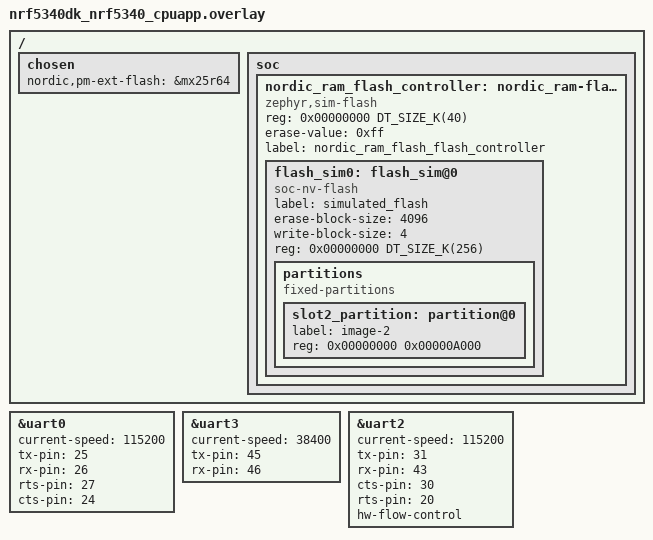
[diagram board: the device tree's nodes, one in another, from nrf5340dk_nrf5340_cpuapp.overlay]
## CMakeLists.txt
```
# SPDX-License-Identifier: Apache-2.0

cmake_minimum_required(VERSION 3.20.0)

list(APPEND ZEPHYR_EXTRA_MODULES ${CMAKE_CURRENT_SOURCE_DIR}/../ubxlib)
find_package(Zephyr REQUIRED HINTS $ENV{ZEPHYR_BASE})
project(celllocate_wifi_example)

FILE(GLOB app_sources src/*.c)
FILE(GLOB head_sources src/*.h)

target_include_directories(app PRIVATE ${CMAKE_CURRENT_SOURCE_DIR}/src)
target_sources(app PRIVATE ${app_sources})
target_sources(app PRIVATE ${head_sources})
```

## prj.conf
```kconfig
CONFIG_SOC_SERIES_NRF53X=y
CONFIG_SERIAL=y
CONFIG_UART_NRFX=y

CONFIG_CONSOLE_SUBSYS=y
CONFIG_CONSOLE_GETCHAR=y


# docs at https://docs.zephyrproject.org/latest/reference/kconfig/index.html
CONFIG_DEBUG=y
CONFIG_MINIMAL_LIBC=n
# This is the memory used by the porting layer
CONFIG_HEAP_MEM_POOL_SIZE=131072
CONFIG_USERSPACE=y
CONFIG_NET_BUF_USER_DATA_SIZE=4

CONFIG_MINIMAL_LIBC_MALLOC=n

# Enable ubxlib
CONFIG_UBXLIB=y

#CONFIG_UBXLIB_GNSS=y

CONFIG_UART_INTERRUPT_DRIVEN=y

#To get uPortTaskStackMinFree() working
CONFIG_INIT_STACKS=y
CONFIG_THREAD_STACK_INFO=y
CONFIG_THREAD_NAME=y

# To be able to use semaphore from ISR
CONFIG_IRQ_OFFLOAD=y

#Sufficient main stack to pass all tests and leave
#5 kbytes slack for user code
CONFIG_MAIN_STACK_SIZE=7048

# Add the basic Zephyr random number generator.
# IMPORTANT: this is only psuedo-random and is unlikely
# to be  sufficient for your needs, please check/test
# if you are intending to build production code.
CONFIG_TEST_RANDOM_GENERATOR=n
CONFIG_ENTROPY_DEVICE_RANDOM_GENERATOR=n

# Don't hide any potential errors
CONFIG_ASSERT=y

# SEGGER RTT logging instead of UART
CONFIG_LOG=y
CONFIG_LOG_DEFAULT_LEVEL=3
#If Log level 4 is set the log stack size needs to be increased
#CONFIG_LOG_PROCESS_THREAD_STACK_SIZE=8096
CONFIG_USE_SEGGER_RTT=n
CONFIG_RTT_CONSOLE=n
CONFIG_UART_CONSOLE=y
CONFIG_LOG_BACKEND_UART=y
CONFIG_LOG_BACKEND_SHOW_COLOR=y
# End of SEGGER RTT

# Enable debug thread info
CONFIG_OPENOCD_SUPPORT=y
CONFIG_DEBUG_OPTIMIZATIONS=y 
CONFIG_DEBUG_THREAD_INFO=y

# Enable bootloader application
CONFIG_BOOTLOADER_MCUBOOT=y

#Enable shell
CONFIG_SHELL=y
CONFIG_SHELL_STACK_SIZE=4096
CONFIG_SHELL_CMDS=n
CONFIG_KERNEL_SHELL=n
CONFIG_DEVICE_SHELL=n
CONFIG_DEVMEM_SHELL=n
CONFIG_FLASH_SHELL=n
CONFIG_PWM_SHELL=n
CONFIG_CLOCK_CONTROL_NRF_SHELL=n
CONFIG_I2C_SHELL=n
```

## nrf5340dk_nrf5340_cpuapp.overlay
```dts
/*
 * Copyright (c) 2021 Nordic Semiconductor ASA
 *
 * SPDX-License-Identifier: LicenseRef-Nordic-5-Clause
 */

/ {
	chosen {
		nordic,pm-ext-flash = &mx25r64;
	};

	soc {
		/* Add a flash controller which has the compatible
		 * 'zephyr,sim-flash'. This will ensure that the flash
		 * simulator can use it. None of the other properties in this
		 * node is used for anything.
		 */
		nordic_ram_flash_controller: nordic_ram-flash-controller@0 {
			compatible = "zephyr,sim-flash";
			reg = <0x00000000 DT_SIZE_K(40)>;
			#address-cells = <1>;
			#size-cells = <1>;
			erase-value = <0xff>;
			label = "nordic_ram_flash_flash_controller";

			/* This node label must match that used in the flash
			 * simulator.
			 */
			flash_sim0: flash_sim@0 {
				status = "okay";
				compatible = "soc-nv-flash";
				label = "simulated_flash";
				erase-block-size = <4096>;
				write-block-size = <4>;
				reg = <0x00000000 DT_SIZE_K(256)>;

				partitions {
					compatible = "fixed-partitions";
					#address-cells = <1>;
					#size-cells = <1>;

					/* This partition must be defined for
					 * MCUboot to find the partition ID
					 * of the primary slot for image 1,
					 * which is stored in this partition.
					 */
					slot2_partition: partition@0 {
						label = "image-2";
						reg = <0x00000000 0x00000A000>;
					};
				};
			};
		};
	};
};


// console uart
&uart0 {
	status = "okay";
	current-speed = <115200>;
	tx-pin = <25>;
	rx-pin = <26>;
	rts-pin = <27>;
	cts-pin = <24>;
};


// MaxM10S uart
&uart3 {
	status = "okay";
	current-speed = <38400>;
	tx-pin = <45>;
	rx-pin = <46>;
};

// Default configuration is set on the NINA-W156 pins, the same UART is also used by SARA-R5
&uart2 {
	status = "okay";
	current-speed = <115200>;
	tx-pin = <31>;  
	rx-pin = <43>;
	cts-pin = <30>;  
	rts-pin = <20>;  
	hw-flow-control;
};
```

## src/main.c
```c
/*
 * Copyright 2020 u-blox
 *
 * Licensed under the Apache License, Version 2.0 (the "License");
 * you may not use this file except in compliance with the License.
 * You may obtain a copy of the License at
 *
 *  http://www.apache.org/licenses/LICENSE-2.0
 *
 * 
 * Unless required by applicable law or agreed to in writing, software
 * distributed under the License is distributed on an "AS IS" BASIS,
 * WITHOUT WARRANTIES OR CONDITIONS OF ANY KIND, either express or implied.
 * See the License for the specific language governing permissions and
 * limitations under the License.
 */


/** 
 * @file main.c
 * @brief Example code for XPLR-IoT-1 Kit to demonstrate CellLocate usage with Sara R5 and Nina-W15 modules.
 */

#include <stddef.h>
#include <stdint.h>
#include <stdbool.h>
#include <stdlib.h>

#include "ubxlib.h"
#include "u_cfg_os_platform_specific.h"

#include <zephyr.h>
#include <console/console.h>
#include <shell/shell.h>
#include <device.h>
#include <devicetree.h>
#include <shell/shell_uart.h> 

#include "module_config.h"


/* ----------------------------------------------------------------
 * COMPILE-TIME MACROS
 * -------------------------------------------------------------- */

#define CELL_LOCATE_TOKEN_MAXLEN   25
#define CELL_LOCATE_SERVER_URL_MAXLEN  100
#define APN_MAXLEN 50
#define U_WIFI_UART_BUFFER_LENGTH_BYTES 600
#define VERIFY(cond, fail_msg) \
    if (!(cond)) {\
        failed(fail_msg); \
    }

/* ------------------------------------------------------------------------------
 * CALLBACK DECLERATIONS
 * -----------------------------------------------------------------------------*/

/** \fn static bool continueCellSearchCallback(uDeviceHandle_t deviceHandle)
 * @brief Indication to stop or continue CellConnect.
 * @param[in] deviceHandle device handle
*/
static bool continueCellSearchCallback(uDeviceHandle_t deviceHandle);


/* ------------------------------------------------------------------------------
 * HELPER FUNCTION DECLERATIONS
 * -----------------------------------------------------------------------------*/

/** \fn void failed(const char *msg)
 * @brief Function to log failed messages.
 * @param[in] msg incoming string - const char array
*/
void failed(const char *msg);

/** \fn char latLongToBits(int32_t thingX1e7, int32_t *pWhole, int32_t *pFraction)
 * @brief Convert a lat/long into a whole number and a bit-after-the-decimal-point that can be printed by a version of printf() 
 * that does not support floating point operations, returning the prefix (either "+" or "-").
 * The result should be printed with printf() format specifiers %c%d.%07d, e.g. something like:
 * int32_t whole;
 * int32_t fraction;
 * printf("%c%d.%07d/%c%d.%07d", latLongToBits(latitudeX1e7, &whole, &fraction),
 *                               whole, fraction,
 *                               latLongToBits(longitudeX1e7, &whole, &fraction),
 *                               whole, fraction);
 */
char latLongToBits(int32_t thingX1e7, int32_t *pWhole, int32_t *pFraction);

/** \fn void printLocation(int32_t latitudeX1e7, int32_t longitudeX1e7)
 * @brief Print lat/long location as a clickable link.
 * @param[in] latitudeX1e7 Latitude upto 7 decimal points
 * @param[in] longitudeX1e7 Longitude upto 7 decimal points
*/
void printLocation(int32_t latitudeX1e7, int32_t longitudeX1e7);

/** \fn int32_t getWifiScanPayload(char *pBuffer, int32_t bufferLength)
 * @brief Get Wi-Fi Access Points 
 * @param[in] pBuffer char array to be filled with APs information
 * @param[in] bufferLength maximum length of the buffer
 * @param[out] count length of the string received after Wi-Fi scan 
*/
int32_t getWifiScanPayload(char *pBuffer, int32_t bufferLength);


/** \fn uint8_t getPosition(char *pBuffer, uLocation_t *location, bool useWifiPayload)
 * @brief Function to get location using CellLocate service
 * @param[in] pBuffer input buffer containing wifi payload if set to USE_WIFI
 * @param[out] location To be filled when location is calculated
 * @param[in] useWifiPayload A flag that indicates to use WIFI location if set to 1. 
*/
uint8_t getPosition(char *pBuffer, uLocation_t *location);

/** \fn static int locationWifiHandler(const struct shell *shell, size_t argc, char **argv)
 * @brief WiFi command handler function to get location using CellLocate service with WiFi
 * @param[in] shell pointer to shell instance
 * @param[in] argc count of arugments
 * @param[in] argv pointer to array of arguments passed. 
*/
static int locationWifiHandler(const struct shell *shell, size_t argc, char **argv);

/** \fn static int locationCellHandler(const struct shell *shell, size_t argc, char **argv)
 * @brief Cell command handler function to get location using CellLocate service
 * @param[in] shell pointer to shell instance
 * @param[in] argc count of arugments
 * @param[in] argv pointer to array of arguments passed. 
*/
static int locationCellHandler(const struct shell *shell, size_t argc, char **argv);

/** \fn static int getConfigParameters(const struct shell *shell, size_t argc, char **argv)
 * @brief Function to read configuration parameters
 * @param[in] shell pointer to shell instance
 * @param[in] argc count of arugments
 * @param[in] argv pointer to array of arguments passed. 
*/
static int getConfigParameters(const struct shell *shell, size_t argc, char **argv);

/** \fn static int setConfigParameters(const struct shell *shell, size_t argc, char **argv)
 * @brief Function to set configuration parameters
 * @param[in] shell pointer to shell instance
 * @param[in] argc count of arugments
 * @param[in] argv pointer to array of arguments passed. 
*/
static int setConfigParameters(const struct shell *shell, size_t argc, char **argv);

/* ------------------------------------------------------------------------------
 * GLOBALS
 * -----------------------------------------------------------------------------*/

int wifiApSignalStrength = -90;
int numWifiAP = 15;
// CELL LOCATE Service Token 
char cellLocateToken[CELL_LOCATE_TOKEN_MAXLEN+1];
// CELL LOCATE Server address
char cellLocateServerUrl[CELL_LOCATE_SERVER_URL_MAXLEN+1]="cell-live1.services.u-blox.com";
// APN name to set for the network
char aPN[APN_MAXLEN+1]="tsiot";
// Timeout for Cell Registration in seconds
int32_t cellRegistrationTimeout = 40; 
// variable to keep connection attempt time
uint32_t cellNetConnectStartTime;
// flag to indicate whether the configuration is done or not 
bool configurationDone = false;

/* ------------------------------------------------------------------------------
 * CALLBACK IMPLEMENTATION
 * -----------------------------------------------------------------------------*/

static bool continueCellSearchCallback(uDeviceHandle_t deviceHandle)
{
    return (k_uptime_get() - cellNetConnectStartTime < (cellRegistrationTimeout*1000));
}

/* ------------------------------------------------------------------------------
 * HELPER FUNCTION IMPLEMENTATION
 * -----------------------------------------------------------------------------*/

void failed(const char *msg)
{
    uPortLog(msg);
    while(1);
}

char latLongToBits(int32_t thingX1e7, int32_t *pWhole, int32_t *pFraction)
{
    char prefix = '+';

    // Deal with the sign
    if (thingX1e7 < 0) {
        thingX1e7 = -thingX1e7;
        prefix = '-';
    }
    *pWhole = thingX1e7 / 10000000;
    *pFraction = thingX1e7 % 10000000;

    return prefix;
}

void printLocation(int32_t latitudeX1e7, int32_t longitudeX1e7)
{
    char prefixLat ;
    char prefixLong;
    int32_t wholeLat = 0;
    int32_t wholeLong = 0;
    int32_t fractionLat = 0;
    int32_t fractionLong = 0;
    prefixLat = latLongToBits(latitudeX1e7, &wholeLat, &fractionLat);
    prefixLong = latLongToBits(longitudeX1e7, &wholeLong, &fractionLong);
    printk("Position Lat: %c%d.%07d, Lon: %c%d.%07d\n",
             prefixLat, wholeLat, fractionLat, prefixLong, wholeLong,
             fractionLong);
    printk("Map URL: https://maps.google.com/?q=%c%d.%07d,%c%d.%07d\n",
             prefixLat, wholeLat, fractionLat, prefixLong, wholeLong,
             fractionLong);
}

int32_t getWifiScanPayload(char *pBuffer, int32_t bufferLength)
{
    printk("Preparing to get WiFi Scan Payload..\r\n");
    int32_t uartHandle;
    uAtClientHandle_t atClientHandle;
    int count = 0;

    memset(pBuffer,0,bufferLength);
    ninaNoraCommEnable();
    setUartConfig(NORAuart);
    printk("Nora UART configured \r\n");
    
    // Open a UART with the recommended buffer length
    // on your chosen UART HW block
    uartHandle = uPortUartOpen(2,
                               115200, NULL,
                               U_WIFI_UART_BUFFER_LENGTH_BYTES,
                               -1,
                               -1,
                               -1,
                               -1);

    // Add an AT client on the UART with the recommended
    // default buffer size.
    atClientHandle = uAtClientAdd(uartHandle,
                                  U_AT_CLIENT_STREAM_TYPE_UART,
                                  NULL,
                                  U_WIFI_UART_BUFFER_LENGTH_BYTES);

    
    // Set printing of AT commands by the cellular driver,
    // which can be useful while debugging.
    uAtClientPrintAtSet(atClientHandle, true);
    uAtClientLock(atClientHandle);
    printk("Setting AT client timeout \r\n");
    uAtClientTimeoutSet(atClientHandle, 5000);
	uAtClientFlush(atClientHandle);
    // Command to perform a Wi-Fi scan operation and outputs Wi-Fi Location fingerprint
    // AT+ULOCWIFIFMT=<numAPs>,<rssiFilter>,<format>
    printk("Requesting Wi-Fi location fingerprint \r\n");
    uAtClientCommandStart(atClientHandle, "AT+ULOCWIFIFMT=");
    uAtClientWriteInt(atClientHandle, numWifiAP);
    uAtClientWriteInt(atClientHandle, wifiApSignalStrength);
    uAtClientWriteInt(atClientHandle, 0);
    uAtClientCommandStop(atClientHandle);

    //Waiting for the response
    if (uAtClientResponseStart(atClientHandle, "+ULOCWIFIFMT:") == 0)
    {
        count = uAtClientReadString(atClientHandle, pBuffer, bufferLength, false);
    }
    uAtClientResponseStop(atClientHandle);
    uAtClientFlush(atClientHandle);
    uAtClientUnlock(atClientHandle);

    uAtClientRemove(atClientHandle);
    uPortUartClose(uartHandle);
    ninaNoraCommDisable();
    printk("NINA Payload(%d) : %s\r\n",count, pBuffer);
    return count;

}

uint8_t getPosition(char *pBuffer, uLocation_t *location)
{
    int32_t uartHandle;
    uAtClientHandle_t atClientHandle;
    uDeviceHandle_t cellHandle;
    
    int32_t numofRetries = 2;
    int32_t errorCode = -1;
    uint8_t locationReceived = U_ERROR_COMMON_UNKNOWN;
    printk("Turning on SARA-R5..\r\n");
    saraR5InitPower();
    setUartConfig(SARAuart);
    
    
    // Open a UART with the recommended buffer length
    // on your chosen UART HW block
    uartHandle = uPortUartOpen(2,
                               115200, NULL,
                               U_CELL_UART_BUFFER_LENGTH_BYTES,
                               -1,
                               -1,
                               -1,
                               -1);

    // Add an AT client on the UART with the recommended
    // default buffer size.
    atClientHandle = uAtClientAdd(uartHandle,
                                  U_AT_CLIENT_STREAM_TYPE_UART,
                                  NULL,
                                  U_CELL_AT_BUFFER_LENGTH_BYTES);

    uCellAdd(U_CELL_MODULE_TYPE_SARA_R5,
                          atClientHandle,
                          -1,
                          -1,
                          -1, false, &cellHandle);

    // Set printing of AT commands by the cellular driver,
    // which can be useful while debugging.                      
    uAtClientPrintAtSet(atClientHandle, true);
    uAtClientLock(atClientHandle);
    
    // AT command To disable echo
    uAtClientCommandStart(atClientHandle, "ATE0");
    uAtClientCommandStopReadResponse(atClientHandle);
    
    // AT+CMEE AT command enable or disable the use of result code
    // Enable +CME ERROR: result code and use verbose values
    uAtClientCommandStart(atClientHandle, "AT+CMEE=2");
    uAtClientCommandStopReadResponse(atClientHandle);
    uAtClientUnlock(atClientHandle);
    cellNetConnectStartTime = k_uptime_get();
    for (int i= 0; i< numofRetries &&  errorCode!= 0; i++){
        errorCode = uCellNetConnect(cellHandle, NULL, aPN, NULL, NULL, continueCellSearchCallback);
        uPortTaskBlock (500);
    }
    if (errorCode == 0) {
        // Configure Cell Locate service
        if (uCellLocSetServer(cellHandle, cellLocateToken, cellLocateServerUrl, NULL)==0){ 
            
            if (pBuffer != NULL){
                // feed wifi scan info to cellular module
                uAtClientLock(atClientHandle);

                // Configures the external location sensor used with the +ULOC command
                // Observation tags message in hexadecimal format
                // Set AT+ULOCEXT=<ULOCEXT_string>
                uAtClientCommandStart(atClientHandle, "AT+ULOCEXT=");
                uAtClientWriteString(atClientHandle, pBuffer, true);
                uAtClientCommandStopReadResponse(atClientHandle);
                uAtClientUnlock(atClientHandle);
            }
            
            // Now get location using Cell Locate
            if (uLocationGet(cellHandle, U_LOCATION_TYPE_CLOUD_CELL_LOCATE,
                            NULL, NULL,
                            location, NULL) == 0) {
                locationReceived = U_ERROR_COMMON_SUCCESS;

            } 
            
        }
    }
    else {
        printk("Cellular module not able to connect to network.\r\n");
    }
    
    uCellRemove(cellHandle);
    uAtClientRemove(atClientHandle);
    uPortUartClose(uartHandle);
    saraR5Disable();
    printk("SARA-R5 powered off \r\n");
    return locationReceived;
}

static int locationWifiHandler(const struct shell *shell, size_t argc, char **argv)
{
    if (configurationDone == false){
        shell_print(shell, "Before requesting location please complete the parameter configuration using config command\r\n");
        return 1;
    }
    unsigned char buffer[1023];
    uLocation_t location;
    int32_t rc = U_ERROR_COMMON_NOT_INITIALISED;
    if (getWifiScanPayload(buffer, sizeof(buffer)) > 0 )
    {
        if (getPosition(buffer, &location) == U_ERROR_COMMON_SUCCESS) {
            printLocation((int32_t)location.latitudeX1e7, (int32_t)location.longitudeX1e7);
            rc = U_ERROR_COMMON_SUCCESS;
        }
        else {
            shell_print(shell, "Could not get location.\r\n");
        }
    }
    else {
        shell_print(shell, "No WiFi AP information available. Please adjust filter conditions according to the environment\r\n");
    }
    
    return 0;
    
}

static int locationCellHandler(const struct shell *shell, size_t argc, char **argv)
{
    if (configurationDone == false){
        shell_print(shell, "Before requesting location please complete the parameter configurtion using config command\r\n");
        return 1;
    }
    int32_t rc = U_ERROR_COMMON_UNKNOWN;
    uLocation_t location;
    if (getPosition(NULL, &location) == U_ERROR_COMMON_SUCCESS) {
        printLocation((int32_t)location.latitudeX1e7, (int32_t)location.longitudeX1e7);
        rc = U_ERROR_COMMON_SUCCESS;
    }
    else {
        printk("Could not get location.\r\n");
    }
    return 0;
}

static int getConfigParameters(const struct shell *shell, size_t argc, char **argv)
{
    shell_print(shell, "CellLocateServerURL: %s, Token: %s, APN: %s, CellRegistrationTimeout: %d, NumWifiAp: %d, WifiApSignalStrength: %d\r\n",\
    cellLocateServerUrl, \
    cellLocateToken,\
    aPN,\
    cellRegistrationTimeout, \
    numWifiAP,\
    wifiApSignalStrength);
    
    return 0;

}

static int setConfigParameters(const struct shell *shell, size_t argc, char **argv)
{
    if (argc == 7){
        bool invalid = false;
        uint32_t integerParameter;
        // checks parameters validity
        if( strlen( argv[1] ) >= CELL_LOCATE_SERVER_URL_MAXLEN ){
            shell_error( shell," CellLocateServerURL length cannot be greater than %d\r\n", CELL_LOCATE_SERVER_URL_MAXLEN );    
            invalid = true;
        }
        if( strlen( argv[2] )  >= CELL_LOCATE_TOKEN_MAXLEN ){
            shell_error( shell,"Token length cannot be greater than %d\r\n", CELL_LOCATE_TOKEN_MAXLEN );    
            invalid = true;
        }
        if( strlen( argv[3] ) >= APN_MAXLEN ){
            shell_error( shell,"APN length cannot be greater than %d\r\n", APN_MAXLEN );    
            invalid = true;
        }
        integerParameter = atoi(argv[4]);
        if(integerParameter < 0 && integerParameter >= 300 ){
            shell_error( shell,"CellRegistrationTimeout should be in between 1-300 seconds\r\n");    
            invalid = true;
        }
        integerParameter = atoi(argv[5]);
        if(integerParameter < 5 && integerParameter > 15 ){
            shell_error( shell,"NumWifiAP should be in between 5-15\r\n");    
            invalid = true;
        }
        integerParameter = atoi(argv[6]);
        if(integerParameter < -100 && integerParameter > 0 ){
            shell_error( shell,"WifiApSignalStrength should be in between -100-0\r\n");    
            invalid = true;
        }
        if( invalid ){
            return 1;
        }

        strcpy(cellLocateServerUrl, argv[1]);
        strcpy(cellLocateToken, argv[2]);
        strcpy(aPN, argv[3]);
        cellRegistrationTimeout = atoi(argv[4]);
        numWifiAP = atoi(argv[5]);
        wifiApSignalStrength = atoi(argv[6]);
        configurationDone = true;
        getConfigParameters(shell, argc, argv);

    }
    else {
        shell_print(shell, "Missing params. Please enter all parameters: <CellLocateServerURL> <Token> <APN> <CellRegistrationTimeout(s)> <NumWifiAp> <WifiApSignalStrength(dbm)>\r\n");
    }
    return 0;
}

/* ------------------------------------------------------------------------------
 * SHELL COMMANDS
 * 1- config
 * 	1a- config set <CellLocateServerURL> <Token> <APN> <CellRegistrationTimeout(s)> <NumWifiAp> <WifiApSignalStrength(dbm)
 * 	1b- config get
 * 2- location LocationType 
 * LocationType refers to cell or wifi 
 * -----------------------------------------------------------------------------*/

//2nd level of options 
SHELL_STATIC_SUBCMD_SET_CREATE(location_type,
        SHELL_CMD(wifi, NULL, "Use wifi access points information to get location",
                                               locationWifiHandler),
        SHELL_CMD(cell,   NULL, "Use cellular scan information to get location", locationCellHandler),
        SHELL_SUBCMD_SET_END
);
SHELL_STATIC_SUBCMD_SET_CREATE(config_sub_cmd,
        SHELL_CMD(get, NULL, "read configuration parameters",
                                               getConfigParameters),
        SHELL_CMD(set,   NULL, "set configuration parameters: <CellLocateServerURL> <Token> <APN> <CellRegistrationTimeout(s)> <NumWifiAp> <WifiApSignalStrength(dbm)>", setConfigParameters),
        SHELL_SUBCMD_SET_END
);

//1st level of options
SHELL_CMD_REGISTER(location, &location_type, "location command", NULL);
SHELL_CMD_REGISTER(config, &config_sub_cmd, "Configuration of parameters", NULL);
/* ----------------------------------------------------------------
 * MAIN FUNCTION
 * -------------------------------------------------------------- */

void main(void)
{   
    nina15InitPower();
    printk("NINA-W15 powered on \r\n");
    VERIFY(uPortInit() == 0, "uPortInit failed\r\n");
    uAtClientInit();
    uDeviceInit(); 
    uCellInit();
    printk("Enter your required shell commands. Type help for further details");
	
}
```

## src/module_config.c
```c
/*
 * Copyright 2020 u-blox
 *
 * Licensed under the Apache License, Version 2.0 (the "License");
 * you may not use this file except in compliance with the License.
 * You may obtain a copy of the License at
 *
 *  http://www.apache.org/licenses/LICENSE-2.0
 *
 * Unless required by applicable law or agreed to in writing, software
 * distributed under the License is distributed on an "AS IS" BASIS,
 * WITHOUT WARRANTIES OR CONDITIONS OF ANY KIND, either express or implied.
 * See the License for the specific language governing permissions and
 * limitations under the License.
 */


/** 
 * @file module_config.c
 * @brief Functions for different configurations of all the modules on XPLR-IOT-1 Kit
 */

#include "module_config.h"
#include <zephyr.h>
#include <hal/nrf_gpio.h>
#include <hal/nrf_uarte.h>
#include <drivers/uart.h>


/*!
 * @brief Sara uart configuration 
 */
UARTE_PSEL_Type SARA ={
    SARA_UART_RTS,
    SARA_UART_TX,
    SARA_UART_CTS,
    SARA_UART_RX
};

/*!
 * @brief Nora uart configuration 
 */
UARTE_PSEL_Type NORA ={
    NORA_UART_RTS,
    NORA_UART_TX,
    NORA_UART_CTS,
    NORA_UART_RX
};


/** \fn nina15ResetEnable(void)
 * @brief Enabling reset on Nina-W15
*/
void nina15ResetEnable(void)
{
    // Apply VCC to NINA
    nrf_gpio_cfg_output((uint32_t) NINA_RESET_PIN);
    nrf_gpio_pin_set((uint32_t) NINA_RESET_PIN);
}

/** \fn nina15ResetDisable(void)
 * @brief Disabling reset on Nina-W15
*/
void nina15ResetDisable(void)
{
    // Disable VCC to NINA
    nrf_gpio_cfg_output((uint32_t) NINA_RESET_PIN);
    nrf_gpio_pin_clear((uint32_t) NINA_RESET_PIN);
}

/** \fn void nina15Enable(void)
 * @brief Enabling Nina-W15 
*/
void nina15Enable(void)
{
    // Apply VCC to NINA
    nrf_gpio_cfg_output((uint32_t) NINA_EN_PIN);
    nrf_gpio_pin_set((uint32_t) NINA_EN_PIN);
}

/** \fn void nina15Disable(void)
 * @brief Disabling Nina-W15
*/
void nina15Disable(void)
{
    // Disable VCC to NINA
    nrf_gpio_cfg_output((uint32_t) NINA_EN_PIN);
    nrf_gpio_pin_clear((uint32_t) NINA_EN_PIN);
}

/** \fn void ninaNoraCommEnable(void)
 * @brief Enabling communication between Nina-W15 and Nora-B1
*/
void ninaNoraCommEnable(void)
{
    // Select UARTE Comm, UART-BRIDGE comm de-select
    nrf_gpio_cfg_output((uint32_t) NORA_NINA_COMM_EN_PIN);
    nrf_gpio_pin_set((uint32_t) NORA_NINA_COMM_EN_PIN);
}

/** \fn void ninaNoraCommDisable(void)
 * @brief Disabling communication between Nina-W15 and Nora-B1
*/
void ninaNoraCommDisable(void)
{
    nrf_gpio_cfg_output((uint32_t) NORA_NINA_COMM_EN_PIN);
    nrf_gpio_pin_clear((uint32_t) NORA_NINA_COMM_EN_PIN);

}

/** \fn void nina15InitPower(void)
 * @brief Nina-W15 powered ON
*/
void nina15InitPower(void)
{
    nina15Enable();

    // Initialize the NINA module, we will hold it in reset until it is powered toggle reset
    nina15ResetEnable();
    k_sleep(K_MSEC(10));
    nina15ResetDisable();

    // t_Startup time after release of reset UBX-18006647 - R10 (page 23)
    k_sleep(K_MSEC(2600));
}

/** \fn void saraR5InitPower(void)
 * @brief SARA R5 powered ON
*/
void saraR5InitPower(void)
{
    
    nrf_gpio_cfg_output((uint32_t) NORA_EN_SARA_PIN);
    nrf_gpio_cfg_output((uint32_t) SARA_PWR_ON_PIN);
    

    // Power on sequence

    // Apply power to the module and wait a little time
    nrf_gpio_pin_set((uint32_t) NORA_EN_SARA_PIN);
    k_sleep(K_MSEC(500));
    
    //assert POWER_ON pin for a valid time
    nrf_gpio_pin_set((uint32_t) SARA_PWR_ON_PIN);
    k_sleep(K_MSEC(2100));
    //deassert POWER_ON pin
    nrf_gpio_pin_clear((uint32_t) SARA_PWR_ON_PIN);
    
}

/** \fn void saraR5Disable(void)
 * @brief SARA R5 powered OFF
*/
void saraR5Disable(void)
{
    // disable VCC to SaraR5
    nrf_gpio_cfg_output((uint32_t) NORA_EN_SARA_PIN);
    nrf_gpio_pin_clear((uint32_t) NORA_EN_SARA_PIN);
}

/** \fn void max10Enable(void)
 * @brief M10 GNSS receiver enabled
*/
void max10Enable(void)
{
    // Apply VCC to max10
    nrf_gpio_cfg_output((uint32_t) EN_MAX_PIN);
    nrf_gpio_pin_set((uint32_t) EN_MAX_PIN);
}

/** \fn void max10Disable(void)
 * @brief M10 GNSS receiver disabled
*/
void max10Disable(void)
{
    // Apply VCC to
    nrf_gpio_cfg_output((uint32_t) EN_MAX_PIN);
    nrf_gpio_pin_clear((uint32_t) EN_MAX_PIN);
}

/** \fn void max10SafeBootEnable(void)
 * @brief M10 GNSS receiver Safe Boot mode enabled
*/
void max10SafeBootEnable(void)
{
    // Apply VCC to max10
    nrf_gpio_cfg_output((uint32_t) MAX_SAFEBOOT_NOT_PIN);
    nrf_gpio_pin_set((uint32_t) MAX_SAFEBOOT_NOT_PIN);
}

/** \fn void max10SafeBootDisable(void)
 * @brief M10 GNSS receiver safe boot mode disabled
*/
void max10SafeBootDisable(void)
{
    // Apply VCC to
    nrf_gpio_cfg_output((uint32_t) MAX_SAFEBOOT_NOT_PIN);
    nrf_gpio_pin_clear((uint32_t) MAX_SAFEBOOT_NOT_PIN);
}

/** \fn void max10BackupSupplyEnable(void)
 * @brief M10 GNSS receiver backup supply enabled
*/
void max10BackupSupplyEnable(void)
{
    // Apply VCC to max10
    nrf_gpio_cfg_output((uint32_t) MAX_BACKUP_ENABLE_PIN);
    nrf_gpio_pin_set((uint32_t) MAX_BACKUP_ENABLE_PIN);
}

/** \fn void max10BackupSupplyDisable(void)
 * @brief M10 GNSS receiver backup supply disabled
*/
void max10BackupSupplyDisable(void)
{
    // Apply VCC to
    nrf_gpio_cfg_output((uint32_t) MAX_BACKUP_ENABLE_PIN);
    nrf_gpio_pin_clear((uint32_t) MAX_BACKUP_ENABLE_PIN);
}

/** \fn void setUartConfig(uartype type)
 * @brief Setting UART configurations
*/
void setUartConfig(uartype type){

    UARTE_PSEL_Type pins;

    if(type == SARAuart){
        pins = SARA;
    }
    else if(type == NORAuart){
        pins = NORA;
    }
    else{
        return;
    }

    nrf_uarte_disable(NRF_UARTE2_S);
    
    // Set up TX and RX pins.
    nrf_gpio_pin_set(pins.TXD);
    nrf_gpio_cfg_output(pins.TXD);
    nrf_gpio_cfg_input(pins.RXD, NRF_GPIO_PIN_NOPULL);
    nrf_uarte_txrx_pins_set(NRF_UARTE2_S, pins.TXD, pins.RXD);

    // Set up CTS and RTS pins.
    nrf_gpio_cfg_input(pins.CTS, NRF_GPIO_PIN_NOPULL);
    nrf_gpio_pin_set(pins.RTS);
    nrf_gpio_cfg_output(pins.RTS);
    nrf_uarte_hwfc_pins_set(NRF_UARTE2_S, pins.RTS, pins.CTS);

    // enable UARTE
    nrf_uarte_enable(NRF_UARTE2_S);
    // kick-start Rx
    nrf_uarte_task_trigger(NRF_UARTE2_S, NRF_UARTE_TASK_STARTRX);

}
```

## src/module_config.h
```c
/*
 * Copyright 2020 u-blox
 *
 * Licensed under the Apache License, Version 2.0 (the "License");
 * you may not use this file except in compliance with the License.
 * You may obtain a copy of the License at
 *
 *  http://www.apache.org/licenses/LICENSE-2.0
 *
 * Unless required by applicable law or agreed to in writing, software
 * distributed under the License is distributed on an "AS IS" BASIS,
 * WITHOUT WARRANTIES OR CONDITIONS OF ANY KIND, either express or implied.
 * See the License for the specific language governing permissions and
 * limitations under the License.
 */
 
 
/** 
 * @file module_config.h
 * @brief Macros definitions and header of the functions for different configurations of all the modules on XPLR-IOT-1 Kit
 */




/* ------------------------------------------------------------------------------
 * COMPILE-TIME MACROS
 * -----------------------------------------------------------------------------*/


#ifndef _MODULE_CONFIG_H_
#define _MODULE_CONFIG_H_

#define NINA_RESET_PIN          41    /* active low */
#define NINA_EN_PIN              8    /* Applies voltage railt to NINA module */
#define NORA_NINA_COMM_EN_PIN   42    /* Uart routes to NORA */


#define SARA_RESET_PIN 21           /* RESET */
#define SARA_PWR_ON_PIN 9           /* Applies POWER_ON Signal */
#define NORA_EN_SARA_PIN 10         /* Applies voltage rail to  module */
//#define SARA_INT_PIN 33             /* INT Pin Signal */

#define SARA_UART_RX    40
#define SARA_UART_TX    36
#define SARA_UART_CTS   38
#define SARA_UART_RTS   19

#define NORA_UART_RX    43
#define NORA_UART_TX    31
#define NORA_UART_CTS   30
#define NORA_UART_RTS   20

#define EN_MAX_PIN              4    /* enables M10 voltage rail */
#define MAX_BACKUP_ENABLE_PIN   37   /* Applies backup voltage rail to  module */
#define MAX_SAFEBOOT_NOT_PIN    44   /* ! during reset puts device in safeboot mode */ 


/*!
 * @brief SARA and NORA Uart
 */
typedef enum{
    SARAuart,
    NORAuart
}uartype;


/* ------------------------------------------------------------------------------
 * CONFIGURATION FUNCTIONS DECLARATIONS
 * -----------------------------------------------------------------------------*/


void nina15ResetEnable(void);

void nina15ResetDisable(void);

void nina15Enable(void);

void nina15Disable(void);

void ninaNoraCommEnable(void);

void ninaNoraCommDisable(void);


void nina15InitPower(void);

void saraR5InitPower(void);

void saraR5Disable(void);

void max10Enable(void);

void max10Disable(void);

void max10SafeBootEnable(void);

void max10SafeBootDisable(void);

void max10BackupSupplyEnable(void);

void max10BackupSupplyDisable(void);


void setUartConfig(uartype type);

	
#endif // _MODULE_CONFIG_H_
```
